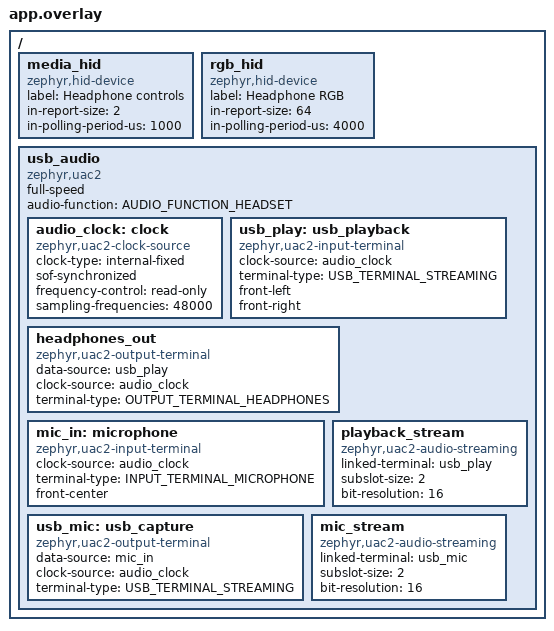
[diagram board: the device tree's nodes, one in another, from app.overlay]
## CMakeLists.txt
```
cmake_minimum_required(VERSION 3.20.0)
list(APPEND BOARD_ROOT "${CMAKE_CURRENT_SOURCE_DIR}")
list(APPEND EXTRA_CONF_FILE "${CMAKE_CURRENT_SOURCE_DIR}/../common/radio.conf")
find_package(Zephyr REQUIRED HINTS $ENV{ZEPHYR_BASE})
project(headphones_dongle)

target_compile_definitions(app PRIVATE HEADPHONES_DONGLE)
target_include_directories(app PRIVATE ../common)
target_sources(app PRIVATE
    src/main.c
    src/usb_audio.c
    src/usb_rgb.c
    ../common/audio.c
    ../common/audio_fifo.c
    ../common/radio.c
    ../common/rgb_frame.c
)
```

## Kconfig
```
mainmenu "Headphones dongle"

config DONGLE_USB_VID
    hex "Assigned dongle USB vendor ID"
    range 0x0000 0xffff
    default 0

config DONGLE_USB_PID
    hex "Assigned dongle USB product ID"
    range 0x0000 0xffff
    default 0

source "Kconfig.zephyr"
```

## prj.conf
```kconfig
CONFIG_GPIO=y
CONFIG_PRINTK=y
CONFIG_CONSOLE=y
CONFIG_USE_SEGGER_RTT=y
CONFIG_RTT_CONSOLE=y
CONFIG_UART_CONSOLE=n
CONFIG_CLOCK_CONTROL_NRF_K32SRC_RC=y
CONFIG_USB_DEVICE_STACK_NEXT=y
CONFIG_USBD_AUDIO2_CLASS=y
CONFIG_USBD_HID_SUPPORT=y
CONFIG_BT_CENTRAL=y
CONFIG_BT_GATT_CLIENT=y
CONFIG_BT_GATT_AUTO_DISCOVER_CCC=y
CONFIG_MAIN_STACK_SIZE=3072
CONFIG_USBD_THREAD_STACK_SIZE=2304
```

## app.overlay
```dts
#include <dt-bindings/usb/audio.h>
#include "../common/flash.dtsi"

/ {
    media_hid: media_hid {
        compatible = "zephyr,hid-device";
        label = "Headphone controls";
        in-report-size = <2>;
        in-polling-period-us = <1000>;
    };

    rgb_hid: rgb_hid {
        compatible = "zephyr,hid-device";
        label = "Headphone RGB";
        in-report-size = <64>;
        in-polling-period-us = <4000>;
    };

    usb_audio: usb_audio {
        compatible = "zephyr,uac2";
        full-speed;
        audio-function = <AUDIO_FUNCTION_HEADSET>;

        audio_clock: clock {
            compatible = "zephyr,uac2-clock-source";
            clock-type = "internal-fixed";
            sof-synchronized;
            frequency-control = "read-only";
            sampling-frequencies = <48000>;
        };

        usb_play: usb_playback {
            compatible = "zephyr,uac2-input-terminal";
            clock-source = <&audio_clock>;
            terminal-type = <USB_TERMINAL_STREAMING>;
            front-left;
            front-right;
        };

        headphones_out: headphones_out {
            compatible = "zephyr,uac2-output-terminal";
            data-source = <&usb_play>;
            clock-source = <&audio_clock>;
            terminal-type = <OUTPUT_TERMINAL_HEADPHONES>;
        };

        mic_in: microphone {
            compatible = "zephyr,uac2-input-terminal";
            clock-source = <&audio_clock>;
            terminal-type = <INPUT_TERMINAL_MICROPHONE>;
            front-center;
        };

        usb_mic: usb_capture {
            compatible = "zephyr,uac2-output-terminal";
            data-source = <&mic_in>;
            clock-source = <&audio_clock>;
            terminal-type = <USB_TERMINAL_STREAMING>;
        };

        playback_stream {
            compatible = "zephyr,uac2-audio-streaming";
            linked-terminal = <&usb_play>;
            subslot-size = <2>;
            bit-resolution = <16>;
        };

        mic_stream {
            compatible = "zephyr,uac2-audio-streaming";
            linked-terminal = <&usb_mic>;
            subslot-size = <2>;
            bit-resolution = <16>;
        };
    };
};
```

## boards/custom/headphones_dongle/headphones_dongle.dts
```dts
/dts-v1/;

#include <nordic/nrf52840_qiaa.dtsi>

/ {
    model = "Headphones USB dongle";
    compatible = "headphones,dongle";

    chosen {
        zephyr,sram = &sram0;
        zephyr,flash = &flash0;
    };
};

&gpiote {
    status = "okay";
};

&gpio0 {
    status = "okay";
};

zephyr_udc0: &usbd {
    status = "okay";
};
```

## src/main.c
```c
#include "audio.h"
#include "audio_control.h"
#include "radio.h"
#include "usb_audio.h"
#include "usb_rgb.h"

#include <zephyr/drivers/gpio.h>
#include <zephyr/kernel.h>
#include <zephyr/sys/printk.h>

static void received(const uint8_t *packet, size_t length)
{
    if (length == 3U && packet[0] == AUDIO_CONTROL) {
        usb_media_enqueue(packet[1]);
        return;
    }
    int16_t pcm[AUDIO_FRAMES];
    if (audio_decode(pcm, packet, length, AUDIO_MONO)) {
        usb_receive_mic(pcm);
    }
}

int main(void)
{
    const struct device *const gpio = DEVICE_DT_GET(DT_NODELABEL(gpio0));
    if (!device_is_ready(gpio) || gpio_pin_configure(gpio, 5, GPIO_OUTPUT_INACTIVE) < 0) {
        return 1;
    }
    int status = usb_audio_start();
    if (status < 0) {
        printk("Dongle USB setup: %d\n", status);
        return 1;
    }
    status = radio_start(received);
    if (status < 0) {
        printk("Dongle radio setup: %d\n", status);
        return 1;
    }

    struct audio_encoder encoder = {0};
    bool linked = false;
    bool last_capture = false;
    uint32_t last_capture_at = 0;
    for (;;) {
        radio_poll();
        const bool active = radio_active();
        if (active != linked) {
            linked = active;
            usb_clear_audio();
            (void)gpio_pin_set(gpio, 5, linked);
            last_capture = !usb_mic_enabled();
        }
        if (linked) {
            const uint32_t now = k_uptime_get_32();
            const bool capture = usb_mic_enabled();
            if (capture != last_capture || now - last_capture_at >= 500U) {
                const uint8_t request[] = {AUDIO_CONTROL, AUDIO_CAPTURE_ENABLE, capture};
                if (radio_send(request, sizeof(request)) == 0) {
                    last_capture = capture;
                    last_capture_at = now;
                }
            }
            int16_t pcm[AUDIO_FRAMES * AUDIO_STEREO];
            if (usb_read_playback(pcm)) {
                uint8_t packet[AUDIO_PACKET_MAX];
                const size_t length = audio_encode(&encoder, packet, pcm, AUDIO_STEREO);
                (void)radio_send(packet, length);
            }
        }
        usb_rgb_poll(linked && !usb_suspended());
        usb_media_poll();
        k_msleep(1);
    }
}
```

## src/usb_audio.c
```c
#include "usb_audio.h"
#include "usb_rgb.h"
#include "audio_control.h"
#include "audio_fifo.h"

#include <errno.h>
#include <zephyr/sys/atomic.h>
#include <zephyr/usb/class/usbd_hid.h>
#include <zephyr/usb/class/usbd_uac2.h>
#include <zephyr/usb/usbd.h>

enum {
    PLAY_BYTES = AUDIO_USB_FRAMES * AUDIO_STEREO * sizeof(int16_t),
    MIC_BYTES = AUDIO_USB_FRAMES * AUDIO_MONO * sizeof(int16_t),
};

AUDIO_FIFO_DEFINE(playback, AUDIO_STEREO);
AUDIO_FIFO_DEFINE(microphone, AUDIO_MONO);
K_MEM_SLAB_DEFINE_STATIC(out_buffers, ROUND_UP(PLAY_BYTES, UDC_BUF_GRANULARITY),
                         5, UDC_BUF_ALIGN);
K_MEM_SLAB_DEFINE_STATIC(in_buffers, ROUND_UP(MIC_BYTES, UDC_BUF_GRANULARITY),
                         5, UDC_BUF_ALIGN);
K_MSGQ_DEFINE(buttons, sizeof(uint8_t), 8, 1);
static atomic_t mic_enabled;
static atomic_t media_enabled;
static atomic_t media_pressed;
static atomic_t media_in_flight;
static uint8_t media_report[2] __aligned(UDC_BUF_ALIGN);
static atomic_t suspended;
static const struct device *const audio = DEVICE_DT_GET(DT_NODELABEL(usb_audio));
static const struct device *const hid = DEVICE_DT_GET(DT_NODELABEL(media_hid));

USBD_DEVICE_DEFINE(dongle_usb, DEVICE_DT_GET(DT_NODELABEL(zephyr_udc0)),
                   CONFIG_DONGLE_USB_VID, CONFIG_DONGLE_USB_PID);
USBD_DESC_LANG_DEFINE(language);
USBD_DESC_PRODUCT_DEFINE(product, "Headphones Dongle");
USBD_CONFIGURATION_DEFINE(configuration, 0, 50, NULL);

static const uint8_t media_descriptor[] = {
    0x05, 0x0c, 0x09, 0x01, 0xa1, 0x01,
    0x15, 0x00, 0x26, 0xff, 0x03,
    0x19, 0x00, 0x2a, 0xff, 0x03,
    0x75, 0x10, 0x95, 0x01, 0x81, 0x00, 0xc0,
};

static void media_ready(const struct device *dev, bool enabled)
{
    ARG_UNUSED(dev);
    atomic_set(&media_enabled, enabled);
    if (!enabled) {
        atomic_clear(&media_pressed);
    }
}

static void media_sent(const struct device *dev, const uint8_t *report)
{
    ARG_UNUSED(dev);
    ARG_UNUSED(report);
    atomic_clear(&media_in_flight);
}

static const struct hid_device_ops media_ops = {
    .iface_ready = media_ready,
    .input_report_done = media_sent,
};

static void terminal_update(const struct device *dev, uint8_t terminal, bool enabled,
                            bool microframes, void *user)
{
    ARG_UNUSED(dev);
    ARG_UNUSED(microframes);
    ARG_UNUSED(user);
    if (terminal == UAC2_ENTITY_ID(DT_NODELABEL(usb_mic))) {
        atomic_set(&mic_enabled, enabled);
        audio_fifo_clear(&microphone);
    } else if (terminal == UAC2_ENTITY_ID(DT_NODELABEL(usb_play))) {
        audio_fifo_clear(&playback);
    }
}

static void *out_buffer(const struct device *dev, uint8_t terminal, uint16_t size, void *user)
{
    ARG_UNUSED(dev);
    ARG_UNUSED(terminal);
    ARG_UNUSED(user);
    void *buffer;
    if (size > PLAY_BYTES || k_mem_slab_alloc(&out_buffers, &buffer, K_NO_WAIT) != 0) {
        return NULL;
    }
    return buffer;
}

static void received(const struct device *dev, uint8_t terminal, void *buffer, uint16_t size,
                     void *user)
{
    ARG_UNUSED(dev);
    ARG_UNUSED(terminal);
    ARG_UNUSED(user);
    if (size != 0U && size <= PLAY_BYTES && size % (AUDIO_STEREO * sizeof(int16_t)) == 0U) {
        audio_fifo_write(&playback, buffer, size / (AUDIO_STEREO * sizeof(int16_t)));
    }
    k_mem_slab_free(&out_buffers, buffer);
}

static void capture_released(const struct device *dev, uint8_t terminal, void *buffer, void *user)
{
    ARG_UNUSED(dev);
    ARG_UNUSED(terminal);
    ARG_UNUSED(user);
    k_mem_slab_free(&in_buffers, buffer);
}

static void sof(const struct device *dev, void *user)
{
    ARG_UNUSED(user);
    void *buffer;
    if (!usb_mic_enabled() || k_mem_slab_alloc(&in_buffers, &buffer, K_NO_WAIT) != 0) {
        return;
    }
    audio_fifo_play(&microphone, buffer, AUDIO_USB_FRAMES);
    if (usbd_uac2_send(dev, UAC2_ENTITY_ID(DT_NODELABEL(usb_mic)), buffer, MIC_BYTES) < 0) {
        k_mem_slab_free(&in_buffers, buffer);
    }
}

static const struct uac2_ops audio_ops = {
    .sof_cb = sof,
    .terminal_update_cb = terminal_update,
    .get_recv_buf = out_buffer,
    .data_recv_cb = received,
    .buf_release_cb = capture_released,
};

static void usb_event(struct usbd_context *context, const struct usbd_msg *message)
{
    if (message->type == USBD_MSG_VBUS_READY) {
        atomic_clear(&suspended);
        (void)usbd_enable(context);
    } else if (message->type == USBD_MSG_VBUS_REMOVED) {
        atomic_clear(&mic_enabled);
        atomic_clear(&media_enabled);
        atomic_clear(&media_pressed);
        atomic_clear(&suspended);
        usb_clear_audio();
        (void)usbd_disable(context);
    } else if (message->type == USBD_MSG_SUSPEND) {
        atomic_set(&suspended, 1);
        usb_clear_audio();
    } else if (message->type == USBD_MSG_RESUME) {
        atomic_clear(&suspended);
    } else if (message->type == USBD_MSG_RESET) {
        atomic_clear(&mic_enabled);
        atomic_clear(&media_enabled);
        atomic_clear(&media_pressed);
        atomic_clear(&suspended);
        usb_clear_audio();
    }
}

int usb_audio_start(void)
{
    if (CONFIG_DONGLE_USB_VID == 0 || CONFIG_DONGLE_USB_PID == 0) {
        return -ENOTSUP;
    }
    if (!device_is_ready(audio) || !device_is_ready(hid)) {
        return -ENODEV;
    }
    usbd_uac2_set_ops(audio, &audio_ops, NULL);
    int status = hid_device_register(hid, media_descriptor, sizeof(media_descriptor), &media_ops);
    if (status == 0) {
        status = usb_rgb_register();
    }
    if (status == 0) {
        status = usbd_add_descriptor(&dongle_usb, &language);
    }
    if (status == 0) {
        status = usbd_add_descriptor(&dongle_usb, &product);
    }
    if (status == 0) {
        status = usbd_add_configuration(&dongle_usb, USBD_SPEED_FS, &configuration);
    }
    if (status == 0) {
        status = usbd_register_all_classes(&dongle_usb, USBD_SPEED_FS, 1, NULL);
    }
    if (status == 0) {
        status = usbd_device_set_code_triple(&dongle_usb, USBD_SPEED_FS,
                                             USB_BCC_MISCELLANEOUS, 0x02, 0x01);
    }
    if (status == 0) {
        status = usbd_msg_register_cb(&dongle_usb, usb_event);
    }
    if (status == 0) {
        status = usbd_init(&dongle_usb);
    }
    if (status == 0 && !usbd_can_detect_vbus(&dongle_usb)) {
        status = usbd_enable(&dongle_usb);
    }
    return status;
}

bool usb_read_playback(int16_t *pcm)
{
    return audio_fifo_read(&playback, pcm, AUDIO_FRAMES);
}

bool usb_mic_enabled(void)
{
    return atomic_get(&mic_enabled) != 0 && !usb_suspended();
}

bool usb_suspended(void)
{
    return atomic_get(&suspended) != 0;
}

void usb_receive_mic(const int16_t *pcm)
{
    if (usb_mic_enabled()) {
        audio_fifo_write(&microphone, pcm, AUDIO_FRAMES);
    }
}

void usb_clear_audio(void)
{
    audio_fifo_clear(&playback);
    audio_fifo_clear(&microphone);
    k_msgq_purge(&buttons);
}

void usb_media_enqueue(uint8_t usage)
{
    if (atomic_get(&media_enabled) && !usb_suspended() &&
        (usage == AUDIO_PLAY_PAUSE || usage == AUDIO_VOLUME_UP || usage == AUDIO_VOLUME_DOWN)) {
        (void)k_msgq_put(&buttons, &usage, K_NO_WAIT);
    }
}

void usb_media_poll(void)
{
    if (!atomic_get(&media_enabled) || usb_suspended() || atomic_get(&media_in_flight)) {
        return;
    }
    const bool release = atomic_get(&media_pressed) != 0;
    uint8_t usage = 0;
    if (!release && k_msgq_get(&buttons, &usage, K_NO_WAIT) != 0) {
        return;
    }
    media_report[0] = usage;
    atomic_set(&media_in_flight, 1);
    if (hid_device_submit_report(hid, sizeof(media_report), media_report) == 0) {
        atomic_set(&media_pressed, !release);
    } else {
        atomic_clear(&media_in_flight);
    }
}
```

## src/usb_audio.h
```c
#ifndef HEADPHONES_DONGLE_USB_AUDIO_H
#define HEADPHONES_DONGLE_USB_AUDIO_H

#include <stdbool.h>
#include <stdint.h>

int usb_audio_start(void);
bool usb_read_playback(int16_t *pcm);
bool usb_mic_enabled(void);
bool usb_suspended(void);
void usb_receive_mic(const int16_t *pcm);
void usb_clear_audio(void);
void usb_media_enqueue(uint8_t usage);
void usb_media_poll(void);

#endif
```

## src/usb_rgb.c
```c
#include "usb_rgb.h"
#include "radio.h"
#include "rgb_frame.h"

#include <errno.h>
#include <string.h>
#include <zephyr/kernel.h>
#include <zephyr/usb/class/usbd_hid.h>

enum { MIN_FRAME_INTERVAL_MS = 33 };

static struct k_spinlock lock;
static struct rgb_frame staged;
static uint8_t pixels[RGB_FRAME_BYTES];
static bool pending;
static uint32_t revision;
static uint32_t last_frame;
static uint32_t last_send;

static void interface_ready(const struct device *dev, bool ready)
{
    ARG_UNUSED(dev);
    if (!ready) {
        k_spinlock_key_t key = k_spin_lock(&lock);
        pending = false;
        staged.have_left = false;
        k_spin_unlock(&lock, key);
    }
}

static int set_report(const struct device *dev, uint8_t type, uint8_t id,
                      uint16_t length, const uint8_t *data)
{
    ARG_UNUSED(dev);
    if (type != HID_REPORT_TYPE_FEATURE || id != RGB_REPORT_ID) {
        return -EINVAL;
    }
    const uint32_t now = k_uptime_get_32();
    k_spinlock_key_t key = k_spin_lock(&lock);
    const int status = rgb_frame_accept(&staged, pixels, data, length, now);
    if (status > 0) {
        ++revision;
        last_frame = now;
        pending = true;
    }
    k_spin_unlock(&lock, key);
    return status < 0 ? status : 0;
}

int usb_rgb_register(void)
{
    const struct device *const hid = DEVICE_DT_GET(DT_NODELABEL(rgb_hid));
    static const struct hid_device_ops ops = {
        .iface_ready = interface_ready,
        .set_report = set_report,
    };
    static const uint8_t descriptor[] = {RGB_HID_DESCRIPTOR_BYTES};
    if (!device_is_ready(hid)) {
        return -ENODEV;
    }
    return hid_device_register(hid, descriptor, sizeof(descriptor), &ops);
}

void usb_rgb_poll(bool linked)
{
    const uint32_t now = k_uptime_get_32();
    if (!linked || now - last_send < MIN_FRAME_INTERVAL_MS) {
        return;
    }
    uint8_t packet[RGB_RADIO_BYTES] = {RGB_COMMAND_FRAME};
    k_spinlock_key_t key = k_spin_lock(&lock);
    pending &= now - last_frame < RGB_TIMEOUT_MS;
    const bool ready = pending;
    const uint32_t sending = revision;
    if (ready) {
        memcpy(packet + 1, pixels, sizeof(pixels));
    }
    k_spin_unlock(&lock, key);

    if (ready && radio_send(packet, sizeof(packet)) == 0) {
        last_send = now;
        key = k_spin_lock(&lock);
        if (revision == sending) {
            pending = false;
        }
        k_spin_unlock(&lock, key);
    }
}
```

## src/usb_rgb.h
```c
#ifndef HEADPHONES_DONGLE_RGB_H
#define HEADPHONES_DONGLE_RGB_H

#include <stdbool.h>

int usb_rgb_register(void);
void usb_rgb_poll(bool linked);

#endif
```
